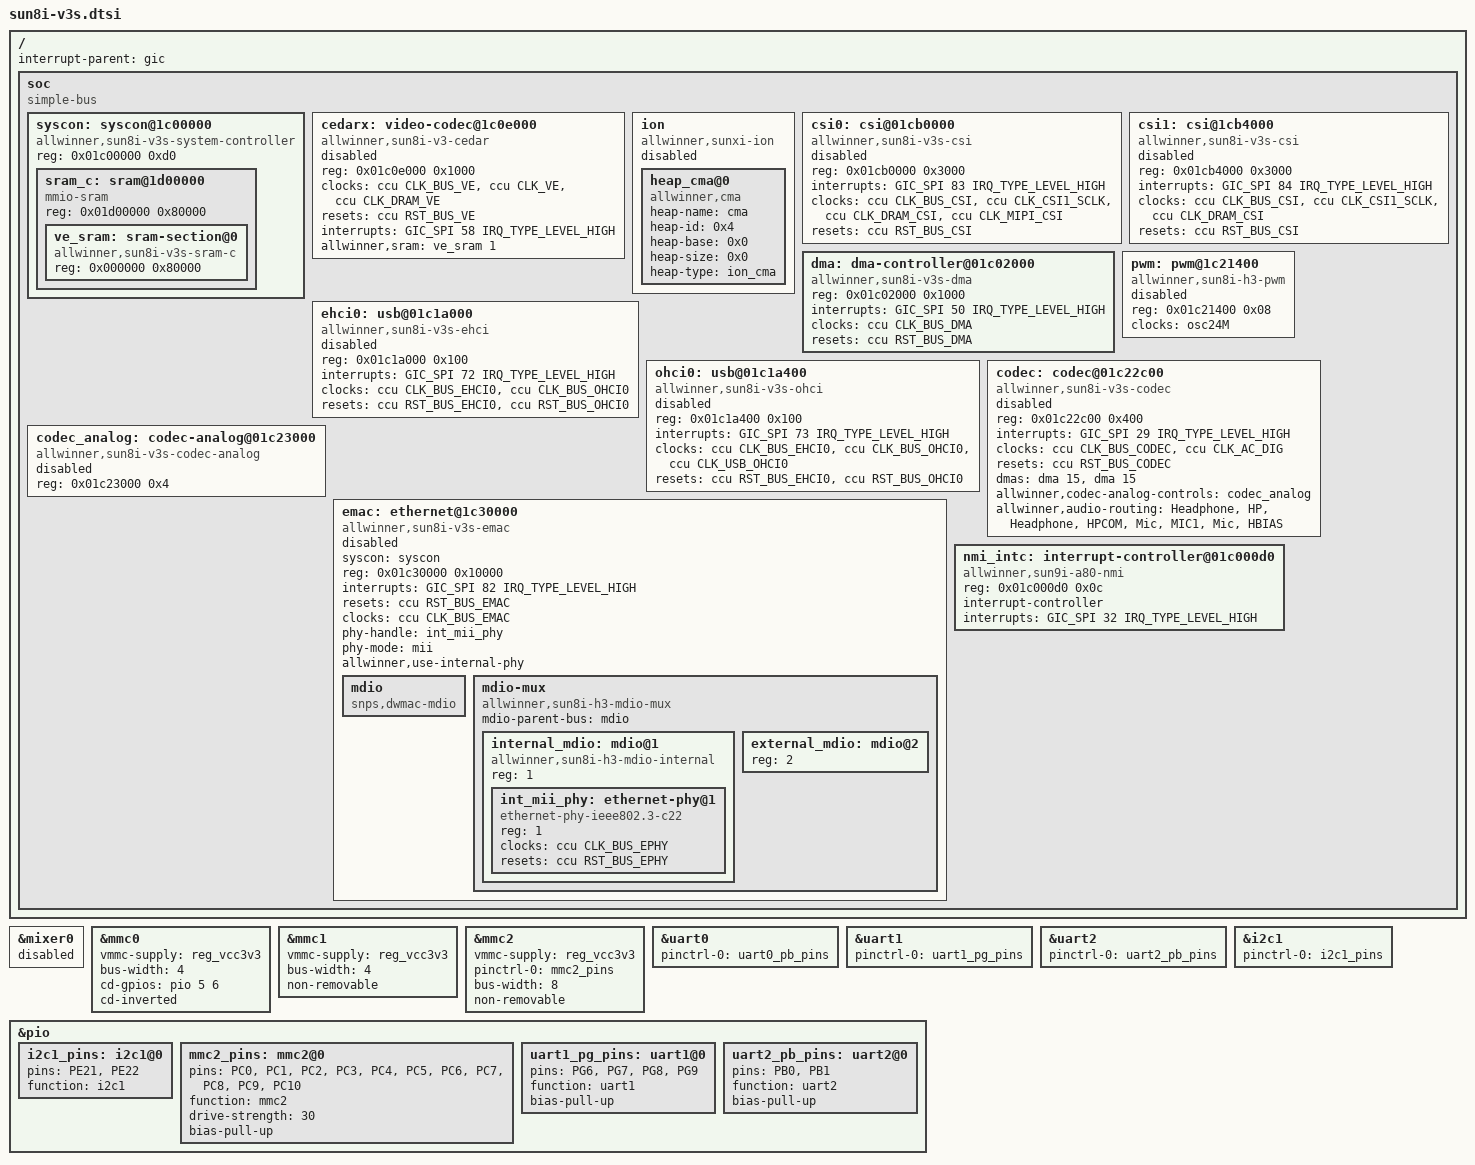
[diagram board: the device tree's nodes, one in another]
/dts-v1/;
#include "sun8i-v3.dtsi"
#include "sunxi-common-regulators.dtsi"
#include <dt-bindings/input/input.h>

/ {
    #address-cells = <1>;
    #size-cells = <1>;
    interrupt-parent = <&gic>;

    soc {
        compatible = "simple-bus";
        #address-cells = <1>;
        #size-cells = <1>;
        ranges;

        syscon: syscon@1c00000 {
            compatible = "allwinner,sun8i-v3s-system-controller", "allwinner,sun8i-h3-system-control", "syscon";
            reg = <0x01c00000 0xd0>;
            #address-cells = <1>;
            #size-cells = <1>;
            ranges;

            sram_c: sram@1d00000 {
                compatible = "mmio-sram";
                reg = <0x01d00000 0x80000>;
                #address-cells = <1>;
                #size-cells = <1>;
                ranges = <0 0x01d00000 0x80000>;

                ve_sram: sram-section@0 {
                    compatible = "allwinner,sun8i-v3s-sram-c", "allwinner,sun4i-a10-sram-c1";
                    reg = <0x000000 0x80000>;
                };
            };
        };

        cedarx: video-codec@1c0e000 {
            compatible = "allwinner,sun8i-v3-cedar";
            reg = <0x01c0e000 0x1000>;
            clocks = <&ccu CLK_BUS_VE>, <&ccu CLK_VE>, <&ccu CLK_DRAM_VE>;
            clock-names = "ahb", "mod", "ram";
            resets = <&ccu RST_BUS_VE>;
            interrupts = <GIC_SPI 58 IRQ_TYPE_LEVEL_HIGH>;
            allwinner,sram = <&ve_sram 1>;
            status = "disabled";
        };
        
        ion: ion {
            compatible = "allwinner,sunxi-ion";
            status = "disabled";
            heap_cma@0{
                compatible = "allwinner,cma";
                heap-name  = "cma";
                heap-id    = <0x4>;
                heap-base  = <0x0>;
                heap-size  = <0x0>;
                heap-type  = "ion_cma";
            };
        };

        csi0: csi@01cb0000 {
            compatible = "allwinner,sun8i-v3s-csi";
            reg = <0x01cb0000 0x3000>;
            interrupts = <GIC_SPI 83 IRQ_TYPE_LEVEL_HIGH>;
            clocks = <&ccu CLK_BUS_CSI>, <&ccu CLK_CSI1_SCLK>, <&ccu CLK_DRAM_CSI>, <&ccu CLK_MIPI_CSI>;
            clock-names = "bus", "mod", "ram", "dphy";
            resets = <&ccu RST_BUS_CSI>;
            status = "disabled";
        };

        csi1: csi@1cb4000 {
            compatible = "allwinner,sun8i-v3s-csi";
            reg = <0x01cb4000 0x3000>;
            interrupts = <GIC_SPI 84 IRQ_TYPE_LEVEL_HIGH>;
            clocks = <&ccu CLK_BUS_CSI>, <&ccu CLK_CSI1_SCLK>, <&ccu CLK_DRAM_CSI>;
            clock-names = "bus", "mod", "ram";
            resets = <&ccu RST_BUS_CSI>;
            status = "disabled";
        };
        
        dma: dma-controller@01c02000 {
            compatible = "allwinner,sun8i-v3s-dma";
            reg = <0x01c02000 0x1000>;
            interrupts = <GIC_SPI 50 IRQ_TYPE_LEVEL_HIGH>;
            clocks = <&ccu CLK_BUS_DMA>;
            resets = <&ccu RST_BUS_DMA>;
            #dma-cells = <1>;
        };
        
        pwm: pwm@1c21400 {
            compatible = "allwinner,sun8i-h3-pwm";
            reg = <0x01c21400 0x08>;
            clocks = <&osc24M>;
            #pwm-cells = <3>;
            status = "disabled";
        };

        ehci0: usb@01c1a000 {
            compatible = "allwinner,sun8i-v3s-ehci", "generic-ehci";
            reg = <0x01c1a000 0x100>;
            interrupts = <GIC_SPI 72 IRQ_TYPE_LEVEL_HIGH>;
            clocks = <&ccu CLK_BUS_EHCI0>, <&ccu CLK_BUS_OHCI0>;
            resets = <&ccu RST_BUS_EHCI0>, <&ccu RST_BUS_OHCI0>;
            status = "disabled";
        };

        ohci0: usb@01c1a400 {
            compatible = "allwinner,sun8i-v3s-ohci", "generic-ohci";
            reg = <0x01c1a400 0x100>;
            interrupts = <GIC_SPI 73 IRQ_TYPE_LEVEL_HIGH>;
            clocks = <&ccu CLK_BUS_EHCI0>, <&ccu CLK_BUS_OHCI0>, <&ccu CLK_USB_OHCI0>;
            resets = <&ccu RST_BUS_EHCI0>, <&ccu RST_BUS_OHCI0>;
            status = "disabled";
        };
            
        codec: codec@01c22c00 {
            #sound-dai-cells = <0>;
            compatible = "allwinner,sun8i-v3s-codec";
            reg = <0x01c22c00 0x400>;
            interrupts = <GIC_SPI 29 IRQ_TYPE_LEVEL_HIGH>;
            clocks = <&ccu CLK_BUS_CODEC>, <&ccu CLK_AC_DIG>;
            clock-names = "apb", "codec";
            resets = <&ccu RST_BUS_CODEC>;
            dmas = <&dma 15>, <&dma 15>;
            dma-names = "rx", "tx";
            allwinner,codec-analog-controls = <&codec_analog>;
            status = "disabled";
        };

        codec_analog: codec-analog@01c23000 {
            compatible = "allwinner,sun8i-v3s-codec-analog";
            reg = <0x01c23000 0x4>;
            status = "disabled";
        };
        
        emac: ethernet@1c30000 {
            compatible = "allwinner,sun8i-v3s-emac";
            syscon = <&syscon>;
            reg = <0x01c30000 0x10000>;
            interrupts = <GIC_SPI 82 IRQ_TYPE_LEVEL_HIGH>;
            interrupt-names = "macirq";
            resets = <&ccu RST_BUS_EMAC>;
            reset-names = "stmmaceth";
            clocks = <&ccu CLK_BUS_EMAC>;
            clock-names = "stmmaceth";
            phy-handle = <&int_mii_phy>;
            phy-mode = "mii";
            #address-cells = <1>;
            #size-cells = <0>;
            status = "disabled";

            mdio: mdio {
                #address-cells = <1>;
                #size-cells = <0>;
                compatible = "snps,dwmac-mdio";
            };

            mdio-mux {
                compatible = "allwinner,sun8i-h3-mdio-mux";
                #address-cells = <1>;
                #size-cells = <0>;
                mdio-parent-bus = <&mdio>;
                /* Only one MDIO is usable at the time */
                internal_mdio: mdio@1 {
                    compatible = "allwinner,sun8i-h3-mdio-internal";
                    reg = <1>;
                    #address-cells = <1>;
                    #size-cells = <0>;
                    int_mii_phy: ethernet-phy@1 {
                        compatible = "ethernet-phy-ieee802.3-c22";
                        reg = <1>;
                        clocks = <&ccu CLK_BUS_EPHY>;
                        resets = <&ccu RST_BUS_EPHY>;
                    };
                };
                external_mdio: mdio@2 {
                    reg = <2>;
                    #address-cells = <1>;
                    #size-cells = <0>;
                };
            };
        };

        nmi_intc: interrupt-controller@01c000d0 {
            compatible = "allwinner,sun9i-a80-nmi";
            reg = <0x01c000d0 0x0c>;
            interrupt-controller;
            #interrupt-cells = <2>;
            interrupts = <GIC_SPI 32 IRQ_TYPE_LEVEL_HIGH>;
        };
    };
};

&mixer0 {
    status = "disabled";
};

&emac {
    phy-handle = <&int_mii_phy>;
    phy-mode = "mii";
    allwinner,use-internal-phy;
};

&mmc0 {
    vmmc-supply = <&reg_vcc3v3>;
    bus-width = <4>;
    cd-gpios = <&pio 5 6 GPIO_ACTIVE_HIGH>;
    cd-inverted;
};

&mmc1 {
    vmmc-supply = <&reg_vcc3v3>;
    bus-width = <4>;
    non-removable;
};

&mmc2 {
    vmmc-supply = <&reg_vcc3v3>;
    pinctrl-0 = <&mmc2_pins>;
    pinctrl-names = "default";
    bus-width = <8>;
    non-removable;
};

&codec {
    allwinner,audio-routing = "Headphone", "HP", "Headphone", "HPCOM", "Mic", "MIC1", "Mic", "HBIAS";
};

&uart0 {
    pinctrl-0 = <&uart0_pb_pins>;
    pinctrl-names = "default";
};

&uart1 {
    pinctrl-0 = <&uart1_pg_pins>;
    pinctrl-names = "default";
};

&uart2 {
    pinctrl-0 = <&uart2_pb_pins>;
    pinctrl-names = "default";
};

&i2c1 {
    pinctrl-0 = <&i2c1_pins>;
    pinctrl-names = "default";
};

&pio {
    i2c1_pins: i2c1@0 {
        pins = "PE21", "PE22";
        function = "i2c1";
    };

    mmc2_pins: mmc2@0 {
        pins = "PC0", "PC1", "PC2", "PC3", "PC4", "PC5", "PC6", "PC7", "PC8", "PC9", "PC10";
        function = "mmc2";
        drive-strength = <30>;
        bias-pull-up;
    };

    uart1_pg_pins: uart1@0 {
        pins = "PG6", "PG7", "PG8", "PG9";
        function = "uart1";
        bias-pull-up;
    };

    uart2_pb_pins: uart2@0 {
        pins = "PB0", "PB1";
        function = "uart2";
        bias-pull-up;
    };
};
